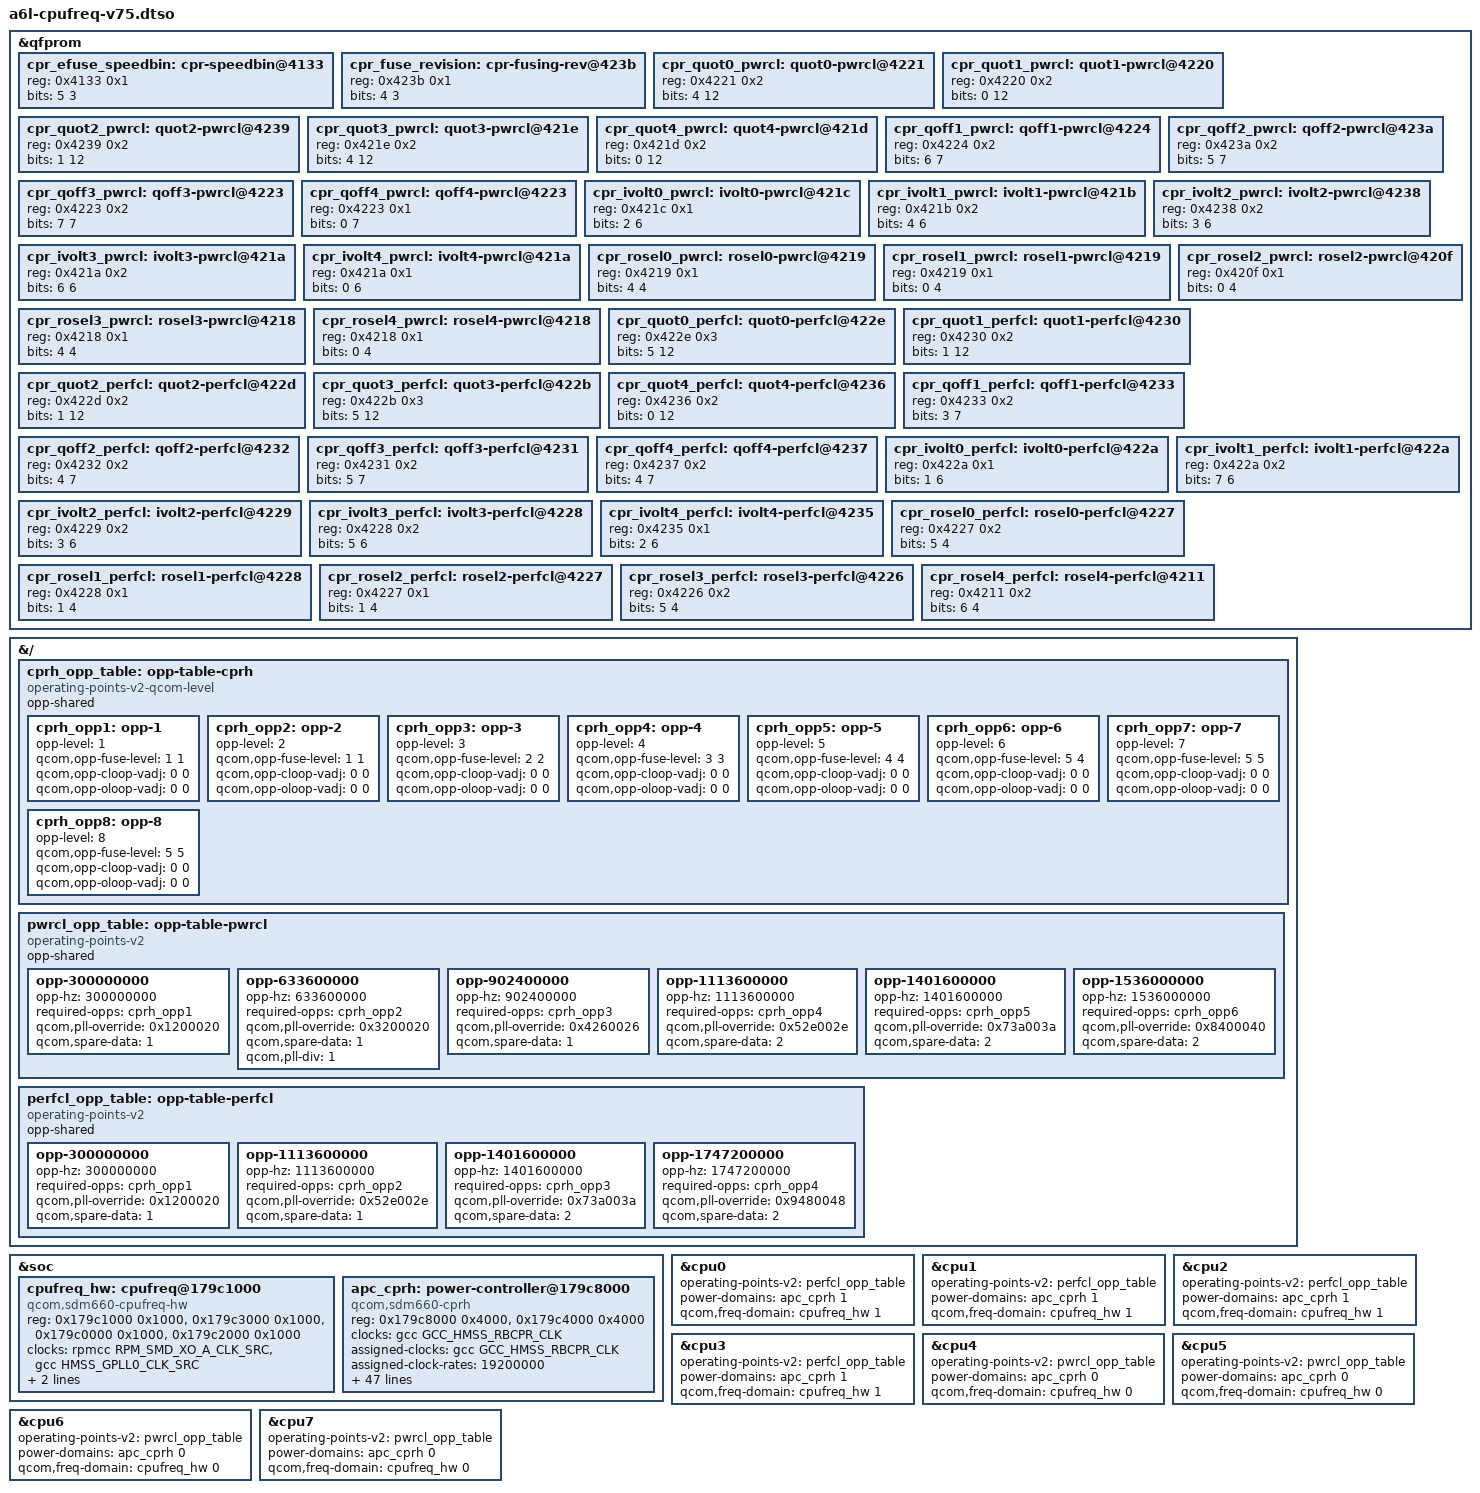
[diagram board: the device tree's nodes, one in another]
// SPDX-License-Identifier: GPL-2.0-only
// GENERATED by gen_sdm660_cpr.py - A6L CPRh + OSM cpufreq (OPEN-LOOP bring-up). VOLTAGE-AFFECTING: attended only.
/dts-v1/;
/plugin/;

#include <dt-bindings/clock/qcom,gcc-sdm660.h>
#include <dt-bindings/clock/qcom,rpmcc.h>
#include <dt-bindings/power/qcom-rpmpd.h>

&qfprom {
	cpr_efuse_speedbin: cpr-speedbin@4133 {
		reg = <0x4133 0x1>;
		bits = <5 3>;
	};
	cpr_fuse_revision: cpr-fusing-rev@423b {
		reg = <0x423b 0x1>;
		bits = <4 3>;
	};
	cpr_quot0_pwrcl: quot0-pwrcl@4221 {
		reg = <0x4221 0x2>;
		bits = <4 12>;
	};
	cpr_quot1_pwrcl: quot1-pwrcl@4220 {
		reg = <0x4220 0x2>;
		bits = <0 12>;
	};
	cpr_quot2_pwrcl: quot2-pwrcl@4239 {
		reg = <0x4239 0x2>;
		bits = <1 12>;
	};
	cpr_quot3_pwrcl: quot3-pwrcl@421e {
		reg = <0x421e 0x2>;
		bits = <4 12>;
	};
	cpr_quot4_pwrcl: quot4-pwrcl@421d {
		reg = <0x421d 0x2>;
		bits = <0 12>;
	};
	cpr_qoff1_pwrcl: qoff1-pwrcl@4224 {
		reg = <0x4224 0x2>;
		bits = <6 7>;
	};
	cpr_qoff2_pwrcl: qoff2-pwrcl@423a {
		reg = <0x423a 0x2>;
		bits = <5 7>;
	};
	cpr_qoff3_pwrcl: qoff3-pwrcl@4223 {
		reg = <0x4223 0x2>;
		bits = <7 7>;
	};
	cpr_qoff4_pwrcl: qoff4-pwrcl@4223 {
		reg = <0x4223 0x1>;
		bits = <0 7>;
	};
	cpr_ivolt0_pwrcl: ivolt0-pwrcl@421c {
		reg = <0x421c 0x1>;
		bits = <2 6>;
	};
	cpr_ivolt1_pwrcl: ivolt1-pwrcl@421b {
		reg = <0x421b 0x2>;
		bits = <4 6>;
	};
	cpr_ivolt2_pwrcl: ivolt2-pwrcl@4238 {
		reg = <0x4238 0x2>;
		bits = <3 6>;
	};
	cpr_ivolt3_pwrcl: ivolt3-pwrcl@421a {
		reg = <0x421a 0x2>;
		bits = <6 6>;
	};
	cpr_ivolt4_pwrcl: ivolt4-pwrcl@421a {
		reg = <0x421a 0x1>;
		bits = <0 6>;
	};
	cpr_rosel0_pwrcl: rosel0-pwrcl@4219 {
		reg = <0x4219 0x1>;
		bits = <4 4>;
	};
	cpr_rosel1_pwrcl: rosel1-pwrcl@4219 {
		reg = <0x4219 0x1>;
		bits = <0 4>;
	};
	cpr_rosel2_pwrcl: rosel2-pwrcl@420f {
		reg = <0x420f 0x1>;
		bits = <0 4>;
	};
	cpr_rosel3_pwrcl: rosel3-pwrcl@4218 {
		reg = <0x4218 0x1>;
		bits = <4 4>;
	};
	cpr_rosel4_pwrcl: rosel4-pwrcl@4218 {
		reg = <0x4218 0x1>;
		bits = <0 4>;
	};
	cpr_quot0_perfcl: quot0-perfcl@422e {
		reg = <0x422e 0x3>;
		bits = <5 12>;
	};
	cpr_quot1_perfcl: quot1-perfcl@4230 {
		reg = <0x4230 0x2>;
		bits = <1 12>;
	};
	cpr_quot2_perfcl: quot2-perfcl@422d {
		reg = <0x422d 0x2>;
		bits = <1 12>;
	};
	cpr_quot3_perfcl: quot3-perfcl@422b {
		reg = <0x422b 0x3>;
		bits = <5 12>;
	};
	cpr_quot4_perfcl: quot4-perfcl@4236 {
		reg = <0x4236 0x2>;
		bits = <0 12>;
	};
	cpr_qoff1_perfcl: qoff1-perfcl@4233 {
		reg = <0x4233 0x2>;
		bits = <3 7>;
	};
	cpr_qoff2_perfcl: qoff2-perfcl@4232 {
		reg = <0x4232 0x2>;
		bits = <4 7>;
	};
	cpr_qoff3_perfcl: qoff3-perfcl@4231 {
		reg = <0x4231 0x2>;
		bits = <5 7>;
	};
	cpr_qoff4_perfcl: qoff4-perfcl@4237 {
		reg = <0x4237 0x2>;
		bits = <4 7>;
	};
	cpr_ivolt0_perfcl: ivolt0-perfcl@422a {
		reg = <0x422a 0x1>;
		bits = <1 6>;
	};
	cpr_ivolt1_perfcl: ivolt1-perfcl@422a {
		reg = <0x422a 0x2>;
		bits = <7 6>;
	};
	cpr_ivolt2_perfcl: ivolt2-perfcl@4229 {
		reg = <0x4229 0x2>;
		bits = <3 6>;
	};
	cpr_ivolt3_perfcl: ivolt3-perfcl@4228 {
		reg = <0x4228 0x2>;
		bits = <5 6>;
	};
	cpr_ivolt4_perfcl: ivolt4-perfcl@4235 {
		reg = <0x4235 0x1>;
		bits = <2 6>;
	};
	cpr_rosel0_perfcl: rosel0-perfcl@4227 {
		reg = <0x4227 0x2>;
		bits = <5 4>;
	};
	cpr_rosel1_perfcl: rosel1-perfcl@4228 {
		reg = <0x4228 0x1>;
		bits = <1 4>;
	};
	cpr_rosel2_perfcl: rosel2-perfcl@4227 {
		reg = <0x4227 0x1>;
		bits = <1 4>;
	};
	cpr_rosel3_perfcl: rosel3-perfcl@4226 {
		reg = <0x4226 0x2>;
		bits = <5 4>;
	};
	cpr_rosel4_perfcl: rosel4-perfcl@4211 {
		reg = <0x4211 0x2>;
		bits = <6 4>;
	};
};

&{/} {
	cprh_opp_table: opp-table-cprh {
		compatible = "operating-points-v2-qcom-level";
		opp-shared;
		cprh_opp1: opp-1 {
			opp-level = <1>;
			qcom,opp-fuse-level = <1 1>;
			qcom,opp-cloop-vadj = <0 0>;
			qcom,opp-oloop-vadj = <0 0>;
		};
		cprh_opp2: opp-2 {
			opp-level = <2>;
			qcom,opp-fuse-level = <1 1>;
			qcom,opp-cloop-vadj = <0 0>;
			qcom,opp-oloop-vadj = <0 0>;
		};
		cprh_opp3: opp-3 {
			opp-level = <3>;
			qcom,opp-fuse-level = <2 2>;
			qcom,opp-cloop-vadj = <0 0>;
			qcom,opp-oloop-vadj = <0 0>;
		};
		cprh_opp4: opp-4 {
			opp-level = <4>;
			qcom,opp-fuse-level = <3 3>;
			qcom,opp-cloop-vadj = <0 0>;
			qcom,opp-oloop-vadj = <0 0>;
		};
		cprh_opp5: opp-5 {
			opp-level = <5>;
			qcom,opp-fuse-level = <4 4>;
			qcom,opp-cloop-vadj = <0 0>;
			qcom,opp-oloop-vadj = <0 0>;
		};
		cprh_opp6: opp-6 {
			opp-level = <6>;
			qcom,opp-fuse-level = <5 4>;
			qcom,opp-cloop-vadj = <0 0>;
			qcom,opp-oloop-vadj = <0 0>;
		};
		cprh_opp7: opp-7 {
			opp-level = <7>;
			qcom,opp-fuse-level = <5 5>;
			qcom,opp-cloop-vadj = <0 0>;
			qcom,opp-oloop-vadj = <0 0>;
		};
		cprh_opp8: opp-8 {
			opp-level = <8>;
			qcom,opp-fuse-level = <5 5>;
			qcom,opp-cloop-vadj = <0 0>;
			qcom,opp-oloop-vadj = <0 0>;
		};
	};

	pwrcl_opp_table: opp-table-pwrcl {
		compatible = "operating-points-v2";
		opp-shared;
		opp-300000000 {
			opp-hz = /bits/ 64 <300000000>;
			required-opps = <&cprh_opp1>;
			qcom,pll-override = <0x1200020>;
			qcom,spare-data = <1>;
		};
		opp-633600000 {
			opp-hz = /bits/ 64 <633600000>;
			required-opps = <&cprh_opp2>;
			qcom,pll-override = <0x3200020>;
			qcom,spare-data = <1>;
			qcom,pll-div = <1>;
		};
		opp-902400000 {
			opp-hz = /bits/ 64 <902400000>;
			required-opps = <&cprh_opp3>;
			qcom,pll-override = <0x4260026>;
			qcom,spare-data = <1>;
		};
		opp-1113600000 {
			opp-hz = /bits/ 64 <1113600000>;
			required-opps = <&cprh_opp4>;
			qcom,pll-override = <0x52e002e>;
			qcom,spare-data = <2>;
		};
		opp-1401600000 {
			opp-hz = /bits/ 64 <1401600000>;
			required-opps = <&cprh_opp5>;
			qcom,pll-override = <0x73a003a>;
			qcom,spare-data = <2>;
		};
		opp-1536000000 {
			opp-hz = /bits/ 64 <1536000000>;
			required-opps = <&cprh_opp6>;
			qcom,pll-override = <0x8400040>;
			qcom,spare-data = <2>;
		};
	};

	perfcl_opp_table: opp-table-perfcl {
		compatible = "operating-points-v2";
		opp-shared;
		opp-300000000 {
			opp-hz = /bits/ 64 <300000000>;
			required-opps = <&cprh_opp1>;
			qcom,pll-override = <0x1200020>;
			qcom,spare-data = <1>;
		};
		opp-1113600000 {
			opp-hz = /bits/ 64 <1113600000>;
			required-opps = <&cprh_opp2>;
			qcom,pll-override = <0x52e002e>;
			qcom,spare-data = <1>;
		};
		opp-1401600000 {
			opp-hz = /bits/ 64 <1401600000>;
			required-opps = <&cprh_opp3>;
			qcom,pll-override = <0x73a003a>;
			qcom,spare-data = <2>;
		};
		opp-1747200000 {
			opp-hz = /bits/ 64 <1747200000>;
			required-opps = <&cprh_opp4>;
			qcom,pll-override = <0x9480048>;
			qcom,spare-data = <2>;
		};
	};

};

&soc {
	cpufreq_hw: cpufreq@179c1000 {
		compatible = "qcom,sdm660-cpufreq-hw";
		reg = <0x179c1000 0x1000>, <0x179c3000 0x1000>,
		      <0x179c0000 0x1000>, <0x179c2000 0x1000>;
		reg-names = "freq-domain0", "freq-domain1",
			    "osm-domain0", "osm-domain1";
		clocks = <&rpmcc RPM_SMD_XO_A_CLK_SRC>, <&gcc HMSS_GPLL0_CLK_SRC>;
		clock-names = "xo", "alternate";
		assigned-clocks = <&gcc HMSS_GPLL0_CLK_SRC>;
		assigned-clock-rates = <300000000>;
		#freq-domain-cells = <1>;
		#clock-cells = <1>;
	};

	apc_cprh: power-controller@179c8000 {
		compatible = "qcom,sdm660-cprh", "qcom,cprh";
		reg = <0x179c8000 0x4000>, <0x179c4000 0x4000>;
		clocks = <&gcc GCC_HMSS_RBCPR_CLK>;
		assigned-clocks = <&gcc GCC_HMSS_RBCPR_CLK>;
		assigned-clock-rates = <19200000>;
		operating-points-v2 = <&cprh_opp_table>;
		power-domains = <&rpmpd SDM660_VDDCX_AO>;
		#power-domain-cells = <1>;
		nvmem-cells = <&cpr_efuse_speedbin>,
			      <&cpr_fuse_revision>,
			      <&cpr_quot0_pwrcl>,
			      <&cpr_quot1_pwrcl>,
			      <&cpr_quot2_pwrcl>,
			      <&cpr_quot3_pwrcl>,
			      <&cpr_quot4_pwrcl>,
			      <&cpr_qoff1_pwrcl>,
			      <&cpr_qoff2_pwrcl>,
			      <&cpr_qoff3_pwrcl>,
			      <&cpr_qoff4_pwrcl>,
			      <&cpr_ivolt0_pwrcl>,
			      <&cpr_ivolt1_pwrcl>,
			      <&cpr_ivolt2_pwrcl>,
			      <&cpr_ivolt3_pwrcl>,
			      <&cpr_ivolt4_pwrcl>,
			      <&cpr_rosel0_pwrcl>,
			      <&cpr_rosel1_pwrcl>,
			      <&cpr_rosel2_pwrcl>,
			      <&cpr_rosel3_pwrcl>,
			      <&cpr_rosel4_pwrcl>,
			      <&cpr_quot0_perfcl>,
			      <&cpr_quot1_perfcl>,
			      <&cpr_quot2_perfcl>,
			      <&cpr_quot3_perfcl>,
			      <&cpr_quot4_perfcl>,
			      <&cpr_qoff1_perfcl>,
			      <&cpr_qoff2_perfcl>,
			      <&cpr_qoff3_perfcl>,
			      <&cpr_qoff4_perfcl>,
			      <&cpr_ivolt0_perfcl>,
			      <&cpr_ivolt1_perfcl>,
			      <&cpr_ivolt2_perfcl>,
			      <&cpr_ivolt3_perfcl>,
			      <&cpr_ivolt4_perfcl>,
			      <&cpr_rosel0_perfcl>,
			      <&cpr_rosel1_perfcl>,
			      <&cpr_rosel2_perfcl>,
			      <&cpr_rosel3_perfcl>,
			      <&cpr_rosel4_perfcl>;
		nvmem-cell-names = "cpr_speed_bin",
				   "cpr_fuse_revision",
				   "cpr0_quotient1",
				   "cpr0_quotient2",
				   "cpr0_quotient3",
				   "cpr0_quotient4",
				   "cpr0_quotient5",
				   "cpr0_quotient_offset2",
				   "cpr0_quotient_offset3",
				   "cpr0_quotient_offset4",
				   "cpr0_quotient_offset5",
				   "cpr0_init_voltage1",
				   "cpr0_init_voltage2",
				   "cpr0_init_voltage3",
				   "cpr0_init_voltage4",
				   "cpr0_init_voltage5",
				   "cpr0_ring_osc1",
				   "cpr0_ring_osc2",
				   "cpr0_ring_osc3",
				   "cpr0_ring_osc4",
				   "cpr0_ring_osc5",
				   "cpr1_quotient1",
				   "cpr1_quotient2",
				   "cpr1_quotient3",
				   "cpr1_quotient4",
				   "cpr1_quotient5",
				   "cpr1_quotient_offset2",
				   "cpr1_quotient_offset3",
				   "cpr1_quotient_offset4",
				   "cpr1_quotient_offset5",
				   "cpr1_init_voltage1",
				   "cpr1_init_voltage2",
				   "cpr1_init_voltage3",
				   "cpr1_init_voltage4",
				   "cpr1_init_voltage5",
				   "cpr1_ring_osc1",
				   "cpr1_ring_osc2",
				   "cpr1_ring_osc3",
				   "cpr1_ring_osc4",
				   "cpr1_ring_osc5";
	};
};

&cpu0 {
	operating-points-v2 = <&perfcl_opp_table>;
	power-domains = <&apc_cprh 1>;
	power-domain-names = "perf";
	qcom,freq-domain = <&cpufreq_hw 1>;
};

&cpu1 {
	operating-points-v2 = <&perfcl_opp_table>;
	power-domains = <&apc_cprh 1>;
	power-domain-names = "perf";
	qcom,freq-domain = <&cpufreq_hw 1>;
};

&cpu2 {
	operating-points-v2 = <&perfcl_opp_table>;
	power-domains = <&apc_cprh 1>;
	power-domain-names = "perf";
	qcom,freq-domain = <&cpufreq_hw 1>;
};

&cpu3 {
	operating-points-v2 = <&perfcl_opp_table>;
	power-domains = <&apc_cprh 1>;
	power-domain-names = "perf";
	qcom,freq-domain = <&cpufreq_hw 1>;
};

&cpu4 {
	operating-points-v2 = <&pwrcl_opp_table>;
	power-domains = <&apc_cprh 0>;
	power-domain-names = "perf";
	qcom,freq-domain = <&cpufreq_hw 0>;
};

&cpu5 {
	operating-points-v2 = <&pwrcl_opp_table>;
	power-domains = <&apc_cprh 0>;
	power-domain-names = "perf";
	qcom,freq-domain = <&cpufreq_hw 0>;
};

&cpu6 {
	operating-points-v2 = <&pwrcl_opp_table>;
	power-domains = <&apc_cprh 0>;
	power-domain-names = "perf";
	qcom,freq-domain = <&cpufreq_hw 0>;
};

&cpu7 {
	operating-points-v2 = <&pwrcl_opp_table>;
	power-domains = <&apc_cprh 0>;
	power-domain-names = "perf";
	qcom,freq-domain = <&cpufreq_hw 0>;
};

